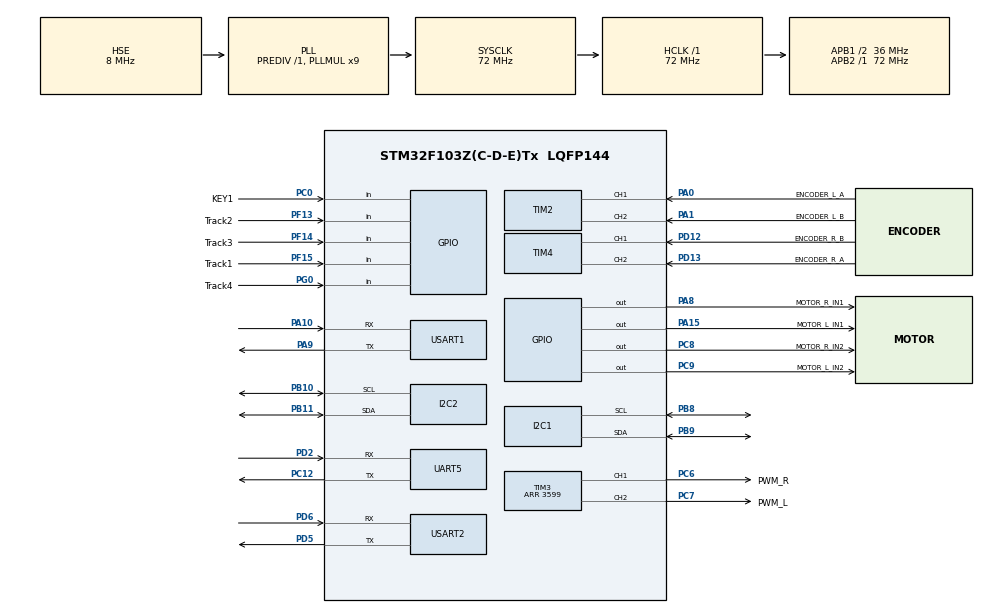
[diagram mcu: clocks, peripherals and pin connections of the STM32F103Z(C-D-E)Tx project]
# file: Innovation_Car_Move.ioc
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Mcu.Family=STM32F1
Mcu.Name=STM32F103Z(C-D-E)Tx
Mcu.Package=LQFP144
NVIC.PriorityGroup=NVIC_PRIORITYGROUP_4
NVIC.TIM1_UP_IRQn=true\:0\:0\:false\:false\:true\:true\:true\:true
NVIC.UART5_IRQn=true\:0\:0\:true\:false\:true\:true\:true\:true
NVIC.USART2_IRQn=true\:1\:0\:true\:false\:true\:true\:true\:true
OSC_IN.Mode=HSE-External-Oscillator
OSC_IN.Signal=RCC_OSC_IN
OSC_OUT.Mode=HSE-External-Oscillator
OSC_OUT.Signal=RCC_OSC_OUT
PA0-WKUP.GPIO_Label=ENCODER_L_A
PA0-WKUP.Signal=S_TIM2_CH1_ETR
PA1.GPIO_Label=ENCODER_L_B
PA1.Signal=S_TIM2_CH2
PA10.Mode=Asynchronous
PA10.Signal=USART1_RX
PA13.Mode=Serial_Wire
PA13.Signal=SYS_JTMS-SWDIO
PA14.Mode=Serial_Wire
PA14.Signal=SYS_JTCK-SWCLK
PA15.GPIO_Label=MOTOR_L_IN1
PA15.Signal=GPIO_Output
PA8.GPIO_Label=MOTOR_R_IN1
PA8.Signal=GPIO_Output
PA9.Mode=Asynchronous
PA9.Signal=USART1_TX
PB10.Mode=I2C
PB10.Signal=I2C2_SCL
PB11.Mode=I2C
PB11.Signal=I2C2_SDA
PB8.Mode=I2C
PB8.Signal=I2C1_SCL
PB9.Mode=I2C
PB9.Signal=I2C1_SDA
PC0.GPIO_Label=KEY1
PC0.GPIO_PuPd=GPIO_PULLUP
PC0.Signal=GPIO_Input
PC12.Mode=Asynchronous
PC12.Signal=UART5_TX
PC6.GPIO_Label=PWM_R
PC6.Signal=S_TIM3_CH1
PC7.GPIO_Label=PWM_L
PC7.Signal=S_TIM3_CH2
PC8.GPIO_Label=MOTOR_R_IN2
PC8.Signal=GPIO_Output
PC9.GPIO_Label=MOTOR_L_IN2
PC9.Signal=GPIO_Output
PD12.GPIO_Label=ENCODER_R_B
PD12.Signal=S_TIM4_CH1
PD13.GPIO_Label=ENCODER_R_A
PD13.Signal=S_TIM4_CH2
PD2.Mode=Asynchronous
PD2.Signal=UART5_RX
PD5.Mode=Asynchronous
PD5.Signal=USART2_TX
PD6.Mode=Asynchronous
PD6.Signal=USART2_RX
PF13.GPIO_Label=Track2
PF13.GPIO_PuPd=GPIO_PULLUP
PF13.Signal=GPIO_Input
PF14.GPIO_Label=Track3
PF14.GPIO_PuPd=GPIO_PULLUP
PF14.Signal=GPIO_Input
PF15.GPIO_Label=Track1
PF15.GPIO_PuPd=GPIO_PULLUP
PF15.Signal=GPIO_Input
PG0.GPIO_Label=Track4
PG0.GPIO_PuPd=GPIO_PULLUP
PG0.Signal=GPIO_Input
ProjectManager.HeapSize=0x200
ProjectManager.StackSize=0x400
ProjectManager.TargetToolchain=STM32CubeIDE
RCC.AHBFreq_Value=72000000
RCC.APB1CLKDivider=RCC_HCLK_DIV2
RCC.APB1Freq_Value=36000000
RCC.APB1TimFreq_Value=72000000
RCC.APB2Freq_Value=72000000
RCC.APB2TimFreq_Value=72000000
RCC.HCLKFreq_Value=72000000
RCC.PLLMUL=RCC_PLL_MUL9
RCC.PLLSourceVirtual=RCC_PLLSOURCE_HSE
RCC.SYSCLKFreq_VALUE=72000000
RCC.SYSCLKSource=RCC_SYSCLKSOURCE_PLLCLK
RCC.USBFreq_Value=72000000
SH.S_TIM2_CH1_ETR.0=TIM2_CH1,Encoder_Interface
SH.S_TIM2_CH2.0=TIM2_CH2,Encoder_Interface
SH.S_TIM3_CH1.0=TIM3_CH1,PWM Generation1 CH1
SH.S_TIM3_CH2.0=TIM3_CH2,PWM Generation2 CH2
SH.S_TIM4_CH1.0=TIM4_CH1,Encoder_Interface
SH.S_TIM4_CH2.0=TIM4_CH2,Encoder_Interface
TIM1.AutoReloadPreload=TIM_AUTORELOAD_PRELOAD_ENABLE
TIM1.Period=1999
TIM1.Prescaler=719
TIM2.EncoderMode=TIM_ENCODERMODE_TI12
TIM3.AutoReloadPreload=TIM_AUTORELOAD_PRELOAD_ENABLE
TIM3.Channel-PWM\ Generation1\ CH1=TIM_CHANNEL_1
TIM3.Channel-PWM\ Generation2\ CH2=TIM_CHANNEL_2
TIM3.Period=3599
TIM4.EncoderMode=TIM_ENCODERMODE_TI12
UART5.VirtualMode=Asynchronous
USART1.VirtualMode=VM_ASYNC
USART2.VirtualMode=VM_ASYNC
VP_TIM1_VS_ClockSourceINT.Mode=Internal
VP_TIM3_VS_ClockSourceINT.Mode=Internal
board=custom

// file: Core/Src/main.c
/* USER CODE BEGIN Header */
/**
  ******************************************************************************
  * @file           : main.c
  * @brief          : Main program body
  ******************************************************************************
  * @attention
  *
  * Copyright (c) 2026 STMicroelectronics.
  * All rights reserved.
  *
  * This software is licensed under terms that can be found in the LICENSE file
  * in the root directory of this software component.
  * If no LICENSE file comes with this software, it is provided AS-IS.
  *
  ******************************************************************************
  */
/* USER CODE END Header */
#include "main.h"
#include "i2c.h"
#include "tim.h"
#include "usart.h"
#include "gpio.h"

/* USER CODE BEGIN Includes */
#include "app.h"
/* USER CODE END Includes */

void SystemClock_Config(void);

int main(void)
{

  /* MCU Configuration--------------------------------------------------------*/

  /* Reset of all peripherals, Initializes the Flash interface and the Systick. */
  HAL_Init();

  /* Configure the system clock */
  SystemClock_Config();

  /* Initialize all configured peripherals */
  MX_GPIO_Init();
  MX_TIM2_Init();
  MX_TIM3_Init();
  MX_TIM4_Init();
  MX_TIM1_Init();
  MX_I2C2_Init();
  MX_USART1_UART_Init();
  MX_USART2_UART_Init();
  MX_UART5_Init();
  MX_I2C1_Init();
  /* USER CODE BEGIN 2 */
  App_Init();
  /* USER CODE END 2 */

  /* Infinite loop */
  /* USER CODE BEGIN WHILE */
  while (1)
  {
      App_Update();
    /* USER CODE END WHILE */

  }
}

void SystemClock_Config(void)
{
  RCC_OscInitTypeDef RCC_OscInitStruct = {0};
  RCC_ClkInitTypeDef RCC_ClkInitStruct = {0};

  /** Initializes the RCC Oscillators according to the specified parameters
  * in the RCC_OscInitTypeDef structure.
  */
  RCC_OscInitStruct.OscillatorType = RCC_OSCILLATORTYPE_HSE;
  RCC_OscInitStruct.HSEState = RCC_HSE_ON;
  RCC_OscInitStruct.HSEPredivValue = RCC_HSE_PREDIV_DIV1;
  RCC_OscInitStruct.HSIState = RCC_HSI_ON;
  RCC_OscInitStruct.PLL.PLLState = RCC_PLL_ON;
  RCC_OscInitStruct.PLL.PLLSource = RCC_PLLSOURCE_HSE;
  RCC_OscInitStruct.PLL.PLLMUL = RCC_PLL_MUL9;
  if (HAL_RCC_OscConfig(&RCC_OscInitStruct) != HAL_OK)
  {
    Error_Handler();
  }

  /** Initializes the CPU, AHB and APB buses clocks
  */
  RCC_ClkInitStruct.ClockType = RCC_CLOCKTYPE_HCLK|RCC_CLOCKTYPE_SYSCLK
                              |RCC_CLOCKTYPE_PCLK1|RCC_CLOCKTYPE_PCLK2;
  RCC_ClkInitStruct.SYSCLKSource = RCC_SYSCLKSOURCE_PLLCLK;
  RCC_ClkInitStruct.AHBCLKDivider = RCC_SYSCLK_DIV1;
  RCC_ClkInitStruct.APB1CLKDivider = RCC_HCLK_DIV2;
  RCC_ClkInitStruct.APB2CLKDivider = RCC_HCLK_DIV1;

  if (HAL_RCC_ClockConfig(&RCC_ClkInitStruct, FLASH_LATENCY_2) != HAL_OK)
  {
    Error_Handler();
  }
}

/* USER CODE BEGIN 4 */

void HAL_TIM_PeriodElapsedCallback(TIM_HandleTypeDef *htim)
{
    if (htim->Instance == TIM1)
    {
        App_TimerISR();
    }
}

/* USER CODE END 4 */

void Error_Handler(void)
{
  __disable_irq();
  while (1)
  {
  }
}
